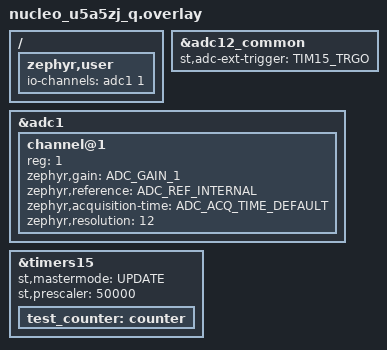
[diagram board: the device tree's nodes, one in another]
/*
 * SPDX-License-Identifier: Apache-2.0
 *
 * Copyright (c) 2023 STMicroelectronics
 */

/ {
	zephyr,user {
		/* adjust channel number according to pinmux in board.dts */
		io-channels = <&adc1 1>;
	};
};

&adc12_common {
	st,adc-ext-trigger = "TIM15_TRGO";
};

&adc1 {
	#address-cells = <1>;
	#size-cells = <0>;

	channel@1 {
		reg = <1>;
		zephyr,gain = "ADC_GAIN_1";
		zephyr,reference = "ADC_REF_INTERNAL";
		zephyr,acquisition-time = <ADC_ACQ_TIME_DEFAULT>;
		zephyr,resolution = <12>;
	};
};

&timers15 {
	st,mastermode = "UPDATE";
	st,prescaler = <50000>;
	status = "okay";

	test_counter: counter {
		status = "okay";
	};
};
